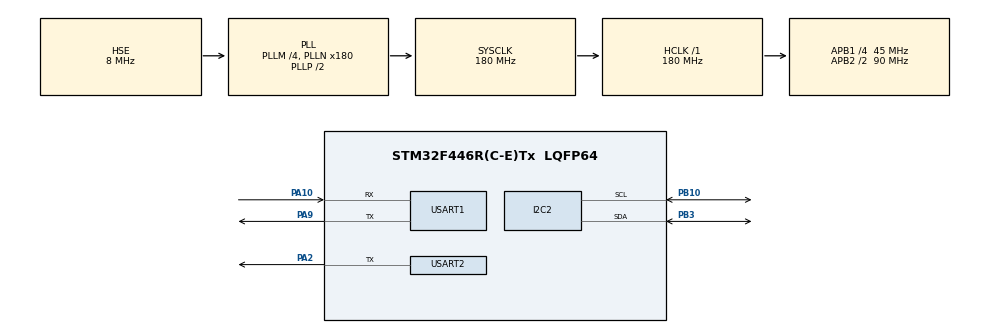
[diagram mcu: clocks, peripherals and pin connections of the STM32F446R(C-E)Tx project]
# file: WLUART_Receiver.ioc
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Dma.I2C2_TX.3.Direction=DMA_MEMORY_TO_PERIPH
Dma.I2C2_TX.3.FIFOMode=DMA_FIFOMODE_DISABLE
Dma.I2C2_TX.3.Instance=DMA1_Stream7
Dma.I2C2_TX.3.MemDataAlignment=DMA_MDATAALIGN_BYTE
Dma.I2C2_TX.3.MemInc=DMA_MINC_ENABLE
Dma.I2C2_TX.3.Mode=DMA_NORMAL
Dma.I2C2_TX.3.PeriphDataAlignment=DMA_PDATAALIGN_BYTE
Dma.I2C2_TX.3.PeriphInc=DMA_PINC_DISABLE
Dma.I2C2_TX.3.Priority=DMA_PRIORITY_LOW
Dma.Request0=USART1_RX
Dma.Request1=USART1_TX
Dma.Request2=USART2_TX
Dma.Request3=I2C2_TX
Dma.USART1_RX.0.Direction=DMA_PERIPH_TO_MEMORY
Dma.USART1_RX.0.FIFOMode=DMA_FIFOMODE_DISABLE
Dma.USART1_RX.0.Instance=DMA2_Stream2
Dma.USART1_RX.0.MemDataAlignment=DMA_MDATAALIGN_BYTE
Dma.USART1_RX.0.MemInc=DMA_MINC_ENABLE
Dma.USART1_RX.0.Mode=DMA_NORMAL
Dma.USART1_RX.0.PeriphDataAlignment=DMA_PDATAALIGN_BYTE
Dma.USART1_RX.0.PeriphInc=DMA_PINC_DISABLE
Dma.USART1_RX.0.Priority=DMA_PRIORITY_LOW
Dma.USART1_TX.1.Direction=DMA_MEMORY_TO_PERIPH
Dma.USART1_TX.1.FIFOMode=DMA_FIFOMODE_DISABLE
Dma.USART1_TX.1.Instance=DMA2_Stream7
Dma.USART1_TX.1.MemDataAlignment=DMA_MDATAALIGN_BYTE
Dma.USART1_TX.1.MemInc=DMA_MINC_ENABLE
Dma.USART1_TX.1.Mode=DMA_NORMAL
Dma.USART1_TX.1.PeriphDataAlignment=DMA_PDATAALIGN_BYTE
Dma.USART1_TX.1.PeriphInc=DMA_PINC_DISABLE
Dma.USART1_TX.1.Priority=DMA_PRIORITY_LOW
Dma.USART2_TX.2.Direction=DMA_MEMORY_TO_PERIPH
Dma.USART2_TX.2.FIFOMode=DMA_FIFOMODE_DISABLE
Dma.USART2_TX.2.Instance=DMA1_Stream6
Dma.USART2_TX.2.MemDataAlignment=DMA_MDATAALIGN_BYTE
Dma.USART2_TX.2.MemInc=DMA_MINC_ENABLE
Dma.USART2_TX.2.Mode=DMA_NORMAL
Dma.USART2_TX.2.PeriphDataAlignment=DMA_PDATAALIGN_BYTE
Dma.USART2_TX.2.PeriphInc=DMA_PINC_DISABLE
Dma.USART2_TX.2.Priority=DMA_PRIORITY_LOW
I2C2.I2C_Mode=I2C_Fast
Mcu.Family=STM32F4
Mcu.Name=STM32F446R(C-E)Tx
Mcu.Package=LQFP64
NVIC.DMA1_Stream6_IRQn=true\:0\:0\:false\:false\:true\:false\:true\:true
NVIC.DMA1_Stream7_IRQn=true\:0\:0\:false\:false\:true\:false\:true\:true
NVIC.DMA2_Stream2_IRQn=true\:0\:0\:false\:false\:true\:false\:true\:true
NVIC.DMA2_Stream7_IRQn=true\:0\:0\:false\:false\:true\:false\:true\:true
NVIC.I2C2_ER_IRQn=true\:0\:0\:false\:false\:true\:true\:true\:true
NVIC.I2C2_EV_IRQn=true\:0\:0\:false\:false\:true\:true\:true\:true
NVIC.PriorityGroup=NVIC_PRIORITYGROUP_4
NVIC.USART1_IRQn=true\:0\:0\:false\:false\:true\:true\:true\:true
NVIC.USART2_IRQn=true\:0\:0\:false\:false\:true\:true\:true\:true
PA10.Mode=Asynchronous
PA10.Signal=USART1_RX
PA13.Mode=Serial_Wire
PA13.Signal=SYS_JTMS-SWDIO
PA14.Mode=Serial_Wire
PA14.Signal=SYS_JTCK-SWCLK
PA2.Mode=Half_duplex(single_wire_mode)
PA2.Signal=USART2_TX
PA9.Mode=Asynchronous
PA9.Signal=USART1_TX
PB10.Mode=I2C
PB10.Signal=I2C2_SCL
PB3.Mode=I2C
PB3.Signal=I2C2_SDA
PH0-OSC_IN.Mode=HSE-External-Clock-Source
PH0-OSC_IN.Signal=RCC_OSC_IN
PH1-OSC_OUT.Mode=HSE-External-Clock-Source
PH1-OSC_OUT.Signal=RCC_OSC_OUT
ProjectManager.HeapSize=0x200
ProjectManager.StackSize=0x400
ProjectManager.TargetToolchain=Makefile
RCC.AHBFreq_Value=180000000
RCC.APB1CLKDivider=RCC_HCLK_DIV4
RCC.APB1Freq_Value=45000000
RCC.APB1TimFreq_Value=90000000
RCC.APB2CLKDivider=RCC_HCLK_DIV2
RCC.APB2Freq_Value=90000000
RCC.APB2TimFreq_Value=180000000
RCC.CortexFreq_Value=180000000
RCC.HCLKFreq_Value=180000000
RCC.HSE_VALUE=8000000
RCC.PLLM=4
RCC.PLLN=180
RCC.PLLSourceVirtual=RCC_PLLSOURCE_HSE
RCC.SYSCLKFreq_VALUE=180000000
RCC.SYSCLKSource=RCC_SYSCLKSOURCE_PLLCLK
RCC.USBFreq_Value=180000000
RCC.VCOOutputFreq_Value=360000000
USART1.VirtualMode=VM_ASYNC
USART2.BaudRate=250000
USART2.Mode=MODE_TX
USART2.VirtualMode=VM_ASYNC
board=custom

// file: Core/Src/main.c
/* USER CODE BEGIN Header */
/**
 ******************************************************************************
 * @file           : main.c
 * @brief          : Main program body
 ******************************************************************************
 * @attention
 *
 * Copyright (c) 2024 STMicroelectronics.
 * All rights reserved.
 *
 * This software is licensed under terms that can be found in the LICENSE file
 * in the root directory of this software component.
 * If no LICENSE file comes with this software, it is provided AS-IS.
 *
 ******************************************************************************
 */
/* USER CODE END Header */
#include "main.h"
#include "dma.h"
#include "gpio.h"
#include "i2c.h"
#include "usart.h"

/* USER CODE BEGIN Includes */

#include "ssd1306.h"
#include <stdio.h>

/* USER CODE END Includes */

/* USER CODE BEGIN PV */

uint8_t uart_receive_buffer
    [UART_RECEIVE_BUFFER_SIZE]; // 设计用于简单场景，不考虑过量数据导致的溢出

/* USER CODE END PV */

void SystemClock_Config(void);

int main(void) {

  /* MCU Configuration--------------------------------------------------------*/

  /* Reset of all peripherals, Initializes the Flash interface and the Systick.
   */
  HAL_Init();

  /* Configure the system clock */
  SystemClock_Config();

  /* Initialize all configured peripherals */
  MX_GPIO_Init();
  MX_DMA_Init();
  MX_USART1_UART_Init();
  MX_I2C2_Init();
  MX_USART2_UART_Init();
  /* USER CODE BEGIN 2 */

  __HAL_UART_ENABLE_IT(&huart1, UART_IT_IDLE); // 使能 USART 1 空闲中断

  if (ssd1306_Init(&hi2c2) != 0) {
    HAL_UART_Transmit_DMA(&huart2, (uint8_t *)"SSD1306 Init ERROR!\n", 20);
    Error_Handler();
  }

  HAL_UART_Transmit_DMA(&huart2, (uint8_t *)"Hello, world!\n", 14);

  HAL_UART_Receive_DMA(&huart1, uart_receive_buffer, UART_RECEIVE_BUFFER_SIZE);

  /* USER CODE END 2 */

  /* Infinite loop */
  while (1) {

  }
}

void SystemClock_Config(void) {
  RCC_OscInitTypeDef RCC_OscInitStruct = {0};
  RCC_ClkInitTypeDef RCC_ClkInitStruct = {0};

  /** Configure the main internal regulator output voltage
   */
  __HAL_RCC_PWR_CLK_ENABLE();
  __HAL_PWR_VOLTAGESCALING_CONFIG(PWR_REGULATOR_VOLTAGE_SCALE1);

  /** Initializes the RCC Oscillators according to the specified parameters
   * in the RCC_OscInitTypeDef structure.
   */
  RCC_OscInitStruct.OscillatorType = RCC_OSCILLATORTYPE_HSE;
  RCC_OscInitStruct.HSEState = RCC_HSE_BYPASS;
  RCC_OscInitStruct.PLL.PLLState = RCC_PLL_ON;
  RCC_OscInitStruct.PLL.PLLSource = RCC_PLLSOURCE_HSE;
  RCC_OscInitStruct.PLL.PLLM = 4;
  RCC_OscInitStruct.PLL.PLLN = 180;
  RCC_OscInitStruct.PLL.PLLP = RCC_PLLP_DIV2;
  RCC_OscInitStruct.PLL.PLLQ = 2;
  RCC_OscInitStruct.PLL.PLLR = 2;
  if (HAL_RCC_OscConfig(&RCC_OscInitStruct) != HAL_OK) {
    Error_Handler();
  }

  /** Activate the Over-Drive mode
   */
  if (HAL_PWREx_EnableOverDrive() != HAL_OK) {
    Error_Handler();
  }

  /** Initializes the CPU, AHB and APB buses clocks
   */
  RCC_ClkInitStruct.ClockType = RCC_CLOCKTYPE_HCLK | RCC_CLOCKTYPE_SYSCLK |
                                RCC_CLOCKTYPE_PCLK1 | RCC_CLOCKTYPE_PCLK2;
  RCC_ClkInitStruct.SYSCLKSource = RCC_SYSCLKSOURCE_PLLCLK;
  RCC_ClkInitStruct.AHBCLKDivider = RCC_SYSCLK_DIV1;
  RCC_ClkInitStruct.APB1CLKDivider = RCC_HCLK_DIV4;
  RCC_ClkInitStruct.APB2CLKDivider = RCC_HCLK_DIV2;

  if (HAL_RCC_ClockConfig(&RCC_ClkInitStruct, FLASH_LATENCY_5) != HAL_OK) {
    Error_Handler();
  }
}

void Error_Handler(void) {
  __disable_irq();
  while (1) {
  }
}

#ifdef USE_FULL_ASSERT
/**
 * @brief  Reports the name of the source file and the source line number
 *         where the assert_param error has occurred.
 * @param  file: pointer to the source file name
 * @param  line: assert_param error line source number
 * @retval None
 */
void assert_failed(uint8_t *file, uint32_t line) {
  /* USER CODE BEGIN 6 */
  /* User can add his own implementation to report the file name and line
     number, ex: printf("Wrong parameters value: file %s on line %d\r\n", file,
     line) */
  /* USER CODE END 6 */
}
#endif /* USE_FULL_ASSERT */
